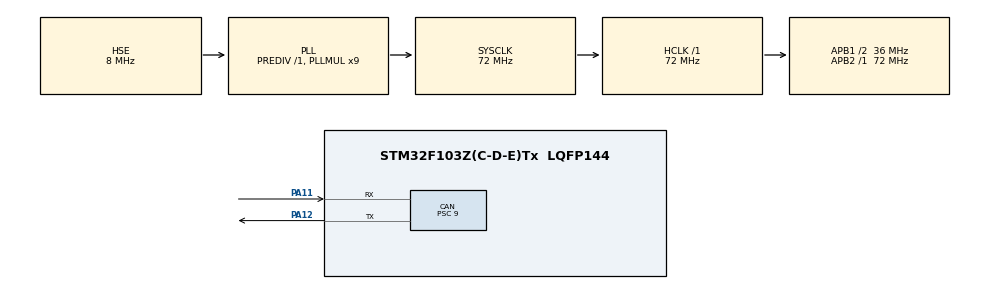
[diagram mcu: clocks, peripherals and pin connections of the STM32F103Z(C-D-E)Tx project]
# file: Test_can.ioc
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CAN.ABOM=ENABLE
CAN.BS2=CAN_BS2_2TQ
CAN.CalculateTimeBit=1000
CAN.CalculateTimeQuantum=250.0
CAN.Prescaler=9
Mcu.Family=STM32F1
Mcu.Name=STM32F103Z(C-D-E)Tx
Mcu.Package=LQFP144
NVIC.PriorityGroup=NVIC_PRIORITYGROUP_4
OSC_IN.Mode=HSE-External-Oscillator
OSC_IN.Signal=RCC_OSC_IN
OSC_OUT.Mode=HSE-External-Oscillator
OSC_OUT.Signal=RCC_OSC_OUT
PA11.Mode=Master
PA11.Signal=CAN_RX
PA12.Mode=Master
PA12.Signal=CAN_TX
PA13.Mode=Serial_Wire
PA13.Signal=SYS_JTMS-SWDIO
PA14.Mode=Serial_Wire
PA14.Signal=SYS_JTCK-SWCLK
ProjectManager.HeapSize=0x200
ProjectManager.StackSize=0x400
ProjectManager.TargetToolchain=MDK-ARM V5.27
RCC.AHBFreq_Value=72000000
RCC.APB1CLKDivider=RCC_HCLK_DIV2
RCC.APB1Freq_Value=36000000
RCC.APB1TimFreq_Value=72000000
RCC.APB2Freq_Value=72000000
RCC.APB2TimFreq_Value=72000000
RCC.HCLKFreq_Value=72000000
RCC.PLLMUL=RCC_PLL_MUL9
RCC.PLLSourceVirtual=RCC_PLLSOURCE_HSE
RCC.SYSCLKFreq_VALUE=72000000
RCC.SYSCLKSource=RCC_SYSCLKSOURCE_PLLCLK
RCC.USBFreq_Value=72000000
board=custom

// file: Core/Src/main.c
/* USER CODE BEGIN Header */
/**
  ******************************************************************************
  * @file           : main.c
  * @brief          : Main program body
  ******************************************************************************
  * @attention
  *
  * <h2><center>&copy; Copyright (c) 2022 STMicroelectronics.
  * All rights reserved.</center></h2>
  *
  * This software component is licensed by ST under BSD 3-Clause license,
  * the "License"; You may not use this file except in compliance with the
  * License. You may obtain a copy of the License at:
  *                        opensource.org/licenses/BSD-3-Clause
  *
  ******************************************************************************
  */
/* USER CODE END Header */
#include "main.h"
#include "can.h"
#include "gpio.h"

void SystemClock_Config(void);

int main(void)
{
  /* USER CODE BEGIN 1 */
	CAN_TxHeaderTypeDef CAN1_TxHander;
	uint8_t TxData[8] = {0};
	int16_t speed = 15000;
  /* USER CODE END 1 */

  /* MCU Configuration--------------------------------------------------------*/

  /* Reset of all peripherals, Initializes the Flash interface and the Systick. */
  HAL_Init();

  /* Configure the system clock */
  SystemClock_Config();

  /* Initialize all configured peripherals */
  MX_GPIO_Init();
  MX_CAN_Init();
  /* USER CODE BEGIN 2 */

	HAL_CAN_Start(&hcan);

	CAN1_TxHander.IDE = CAN_ID_STD;
	CAN1_TxHander.RTR = CAN_RTR_DATA;
	CAN1_TxHander.DLC = 0x08;
	CAN1_TxHander.StdId = 0x200;

	TxData[0] = (uint8_t)(speed >>8);
	TxData[1] = (uint8_t)(speed);
	TxData[2] = 0;
	TxData[3] = 0;
	TxData[4] = 0;
	TxData[5] = 0;
	TxData[6] = 0;
	TxData[7] = 0;

	HAL_CAN_AddTxMessage(&hcan, &CAN1_TxHander, TxData, 0);
  /* USER CODE END 2 */

  /* Infinite loop */
  while (1)
  {

    /* USER CODE BEGIN 3 */
		HAL_CAN_AddTxMessage(&hcan, &CAN1_TxHander, TxData, 0);
  }
  /* USER CODE END 3 */
}

void SystemClock_Config(void)
{
  RCC_OscInitTypeDef RCC_OscInitStruct = {0};
  RCC_ClkInitTypeDef RCC_ClkInitStruct = {0};

  /** Initializes the RCC Oscillators according to the specified parameters
  * in the RCC_OscInitTypeDef structure.
  */
  RCC_OscInitStruct.OscillatorType = RCC_OSCILLATORTYPE_HSE;
  RCC_OscInitStruct.HSEState = RCC_HSE_ON;
  RCC_OscInitStruct.HSEPredivValue = RCC_HSE_PREDIV_DIV1;
  RCC_OscInitStruct.HSIState = RCC_HSI_ON;
  RCC_OscInitStruct.PLL.PLLState = RCC_PLL_ON;
  RCC_OscInitStruct.PLL.PLLSource = RCC_PLLSOURCE_HSE;
  RCC_OscInitStruct.PLL.PLLMUL = RCC_PLL_MUL9;
  if (HAL_RCC_OscConfig(&RCC_OscInitStruct) != HAL_OK)
  {
    Error_Handler();
  }
  /** Initializes the CPU, AHB and APB buses clocks
  */
  RCC_ClkInitStruct.ClockType = RCC_CLOCKTYPE_HCLK|RCC_CLOCKTYPE_SYSCLK
                              |RCC_CLOCKTYPE_PCLK1|RCC_CLOCKTYPE_PCLK2;
  RCC_ClkInitStruct.SYSCLKSource = RCC_SYSCLKSOURCE_PLLCLK;
  RCC_ClkInitStruct.AHBCLKDivider = RCC_SYSCLK_DIV1;
  RCC_ClkInitStruct.APB1CLKDivider = RCC_HCLK_DIV2;
  RCC_ClkInitStruct.APB2CLKDivider = RCC_HCLK_DIV1;

  if (HAL_RCC_ClockConfig(&RCC_ClkInitStruct, FLASH_LATENCY_2) != HAL_OK)
  {
    Error_Handler();
  }
}

void Error_Handler(void)
{
}

/************************ (C) COPYRIGHT STMicroelectronics *****END OF FILE****/
